# nrf9120 register map
Vendor: Nordic Semiconductor; Series: nrf91; File version: 1
CPU: CM33 r0p4, little endian, MPU, FPU, 3 interrupt priority bits, 69 interrupts
Registers are 32-bit, read-write, reset 0x0 unless marked. A register's access mark holds for its fields unless they carry their own. Offsets are from the block's base; [hi:lo] are bit positions; lines under a group give offsets from that group; 'fields as' and 'values as' point back to an identical list.

## APPROTECT_NS — Access Port Protection 0
Base 0x40039000
Same registers: APPROTECT_S 0x50039000
0xE00 SECUREAPPROTECT group — Unspecified
  0x00 DISABLE reset 0x1 — Software disable SECUREAPPROTECT mechanism
    [7:0] DISABLE
      90=SwUnprotected (Software disable SECUREAPPROTECT mechanism)
  0x00 FORCEPROTECT reset 0x1 (alternate view of DISABLE) — Software force SECUREAPPROTECT mechanism
    [9] FORCEPROTECT write-1-sets — Write 0x1 to force enable SECUREAPPROTECT mechanism
      on write: 1=Force (Software force enable SECUREAPPROTECT mechanism)
0xE10 APPROTECT group — Unspecified
  0x00 DISABLE reset 0x1 — Software disable APPROTECT mechanism
    [7:0] DISABLE
      90=SwUnprotected (Software disable APPROTECT mechanism)
  0x00 FORCEPROTECT reset 0x1 (alternate view of DISABLE) — Software force APPROTECT mechanism
    [9] FORCEPROTECT write-1-sets — Write 0x1 to force enable APPROTECT mechanism
      on write: 1=Force (Software force enable APPROTECT mechanism)

## KMU_NS — Key management unit 0
Base 0x40039000; alternate view of APPROTECT_NS
Same registers: KMU_S 0x50039000 (alternate view of APPROTECT_S)
0x00 TASKS_PUSH_KEYSLOT wo — Push a key slot over secure APB
  [0] TASKS_PUSH_KEYSLOT
    1=Trigger task
0x100 EVENTS_KEYSLOT_PUSHED — Key slot successfully pushed over secure APB
  [0] EVENTS_KEYSLOT_PUSHED
    0=NotGenerated (Event not generated); 1=Generated (Event generated)
0x104 EVENTS_KEYSLOT_REVOKED — Key slot has been revoked and cannot be tasked for selection
  [0] EVENTS_KEYSLOT_REVOKED
    values as EVENTS_KEYSLOT_PUSHED.EVENTS_KEYSLOT_PUSHED
0x108 EVENTS_KEYSLOT_ERROR — No key slot selected, no destination address defined, or error during push operation
  [0] EVENTS_KEYSLOT_ERROR
    values as EVENTS_KEYSLOT_PUSHED.EVENTS_KEYSLOT_PUSHED
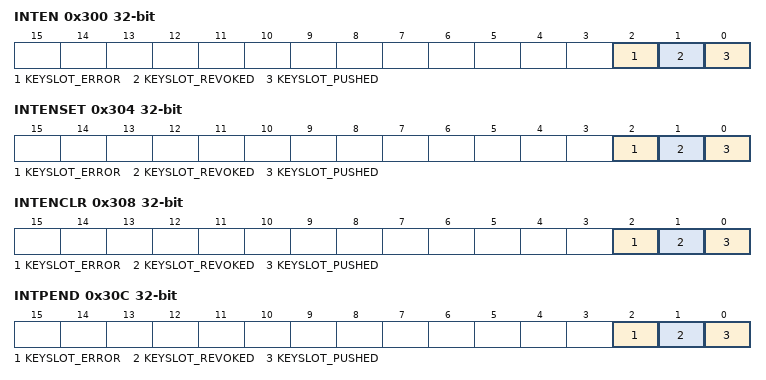
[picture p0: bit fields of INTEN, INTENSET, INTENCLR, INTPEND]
0x300 INTEN — Enable or disable interrupt
  [all] fields
    0=Disabled; 1=Enabled
  [2] KEYSLOT_ERROR — Enable or disable interrupt for event KEYSLOT_ERROR
  [1] KEYSLOT_REVOKED — Enable or disable interrupt for event KEYSLOT_REVOKED
  [0] KEYSLOT_PUSHED — Enable or disable interrupt for event KEYSLOT_PUSHED
0x304 INTENSET — Enable interrupt
  [all] fields
    on read: 0=Disabled (Read: Disabled); 1=Enabled (Read: Enabled) | on write: 1=Set (Enable)
  [2] KEYSLOT_ERROR — Write '1' to enable interrupt for event KEYSLOT_ERROR
  [1] KEYSLOT_REVOKED — Write '1' to enable interrupt for event KEYSLOT_REVOKED
  [0] KEYSLOT_PUSHED — Write '1' to enable interrupt for event KEYSLOT_PUSHED
0x308 INTENCLR — Disable interrupt
  [all] fields
    on read: 0=Disabled (Read: Disabled); 1=Enabled (Read: Enabled) | on write: 1=Clear (Disable)
  [2] KEYSLOT_ERROR — Write '1' to disable interrupt for event KEYSLOT_ERROR
  [1] KEYSLOT_REVOKED — Write '1' to disable interrupt for event KEYSLOT_REVOKED
  [0] KEYSLOT_PUSHED — Write '1' to disable interrupt for event KEYSLOT_PUSHED
0x30C INTPEND ro — Pending interrupts
  [all] fields
    on read: 0=NotPending (Read: Not pending); 1=Pending (Read: Pending)
  [2] KEYSLOT_ERROR — Read pending status of interrupt for event KEYSLOT_ERROR
  [1] KEYSLOT_REVOKED — Read pending status of interrupt for event KEYSLOT_REVOKED
  [0] KEYSLOT_PUSHED — Read pending status of interrupt for event KEYSLOT_PUSHED
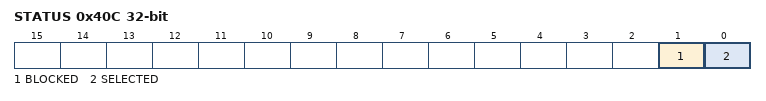
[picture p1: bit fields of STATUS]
0x40C STATUS ro — Status bits for KMU operation
  [1] BLOCKED — Violation status
    0=Disabled (No access violation detected); 1=Enabled (Access violation detected and blocked)
  [0] SELECTED — Key slot ID successfully selected by the KMU
    0=Disabled (No key slot ID selected by KMU); 1=Enabled (Key slot ID successfully selected by KMU)
0x500 SELECTKEYSLOT — Select key slot to be read over AHB or pushed over secure APB when TASKS_PUSH_KEYSLOT is started
  [7:0] ID — Select key slot ID to be read over AHB, or pushed over secure APB, when TASKS_PUSH_KEYSLOT is started. NOTE: ID=0 is not a valid key slot ID. The 0 ID should be used when the KMU is idle or not in use. NOTE: Index N in UICR->KEYSLOT.KEY[N] and UICR->KEYSLOT.CONFIG[N] corresponds to KMU key slot ID=N+1.
